# rCSL_ehrpwm_001 register map
Vendor: Texas Instruments
Peripheral module from a debugger description file (folder OMAPL138_C6748).
Registers are 16-bit, access not given, reset 0x0 unless marked. A register's access mark holds for its fields unless they carry their own. Offsets are as the file gives them; lines under a group give offsets from that group; [hi:lo] are bit positions; {n}, {i} and the like mark numbered series; 'fields as' and 'values as' point back to an identical list; <NAME> marks a mode.

## EHRPWM — Enhanced high-resolution pulse width modulator. This is a combination of the ePWM and HRPWM modules.
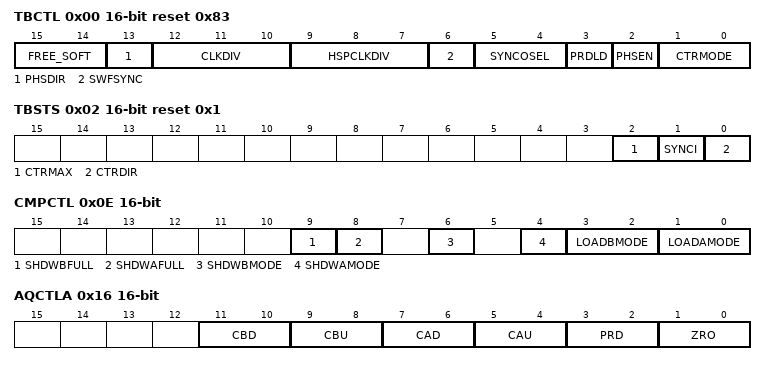
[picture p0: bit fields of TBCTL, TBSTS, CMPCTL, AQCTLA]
0x00 TBCTL rw reset 0x83 — Time-base control
  [15:14] FREE_SOFT — Emulation mode bits.
    0=STOPNEXT; 1=STOPONFULLCYCLE; 2=RUNFREE; 3=RUNFREE
  [13] PHSDIR — Phase direction.
    0=DOWN; 1=UP
  [12:10] CLKDIV — Time-base clock prescale
    0=DIVBY1; 1=DIVBY2; 2=DIVBY4; 3=DIVBY8; 4=DIVBY16; 5=DIVBY32; 6=DIVBY64; 7=DIVBY128
  [9:7] HSPCLKDIV — High speed time-base clock prescale
    0=DIVBY1; 1=DIVBY2; 2=DIVBY4; 3=DIVBY6; 4=DIVBY8; 5=DIVBY10; 6=DIVBY10; 7=DIVBY14
  [6] SWFSYNC — Software forced sync pulse
    0=NOEFFECT; 1=SYNCPULSE
  [5:4] SYNCOSEL — Sync output select
    0=EPWMXSYNCI; 1=TBCTRZERO; 2=TBCTRCMPB; 3=DISABLE
  [3] PRDLD — Active period register load from shadow register select
    0=FROMSHADOW; 1=NOSHADOW
  [2] PHSEN — Counter register load from phase register enable
    0=DISABLE; 1=ENABLE
  [1:0] CTRMODE — Counter mode
    0=UP; 1=DOWN; 2=UPDOWN; 3=STOPFREEZE
0x02 TBSTS reset 0x1 — Time-base status
  [2] CTRMAX rw — Time-base counter max latched status
    0=NOEFFECT; 1=CLEAR
  [1] SYNCI rw — Input sync latched status
    0=NOEFFECT; 1=CLEAR
  [0] CTRDIR ro — Time-base counter direction status
    0=DOWN; 1=UP
0x04 TBPHSHR — Extension for HRPWM phase register. NOTE: although these are documented as part of the HRPWM module, they are actually on the ePWM VBUS, and are therefore represented here.
  [15:8] TBPHSHR rw — High-res extension for TBPHS.
0x06 TBPHS rw — Time-base phase
  [15:0] TBPHS — Time-base counter phase relative to time-base that is supplying sync input.
0x08 TBCTR rw — Time-base counter
0x0A TBPRD rw — Time-base period
  [15:0] TBPRD — Time-base period, i.e. the PWM frequency
0x0E CMPCTL — Counter-compare control
  [9] SHDWBFULL ro — CMPB shadow registers full status flag
    0=NOTFULL; 1=FULL
  [8] SHDWAFULL ro — CMPA shadow registers full status flag
    0=NOTFULL; 1=FULL
  [6] SHDWBMODE rw — CMPB register operating mode
    0=SHADOW; 1=IMMEDIATE
  [4] SHDWAMODE rw — CMPA register operating mode
    0=SHADOW; 1=IMMEDIATE
  [3:2] LOADBMODE rw — CMPB load from shadow select mode
    0=TBCTRZERO; 1=TBCTRPRD; 2=ZEROORPRD; 3=FREEZE
  [1:0] LOADAMODE rw — CMPa load from shadow select mode
    0=TBCTRZERO; 1=TBCTRPRD; 2=ZEROORPRD; 3=FREEZE
0x10 CMPAHR — Extension for HRPWM Counter-compare A. NOTE: although these are documented as part of the HRPWM module, they are actually on the ePWM VBUS, and are therefore represented here.
  [15:8] CMPAHR rw — High-res extension for CMPA.
0x12 CMPA rw — Counter-compare A
  [15:0] CMPA — Compare A value
0x14 CMPB rw — Counter-compare B
  [15:0] CMPB — Compare B value
0x16 AQCTLA — Action-qualifier control for output A
  [all] fields
    0=DONOTHING; 1=EPWMXALOW; 2=EPWMXAHIGH; 3=EPWMXATOGGLE
  [11:10] CBD rw — Action when TBCTR equals active CMPB and counter is decrementing.
  [9:8] CBU rw — Action when TBCTR equals active CMPB and counter is incrementing.
  [7:6] CAD rw — Action when TBCTR equals active CMPA and counter is decrementing.
  [5:4] CAU rw — Action when TBCTR equals active CMPA and counter is incrementing.
  [3:2] PRD rw — Action when TBCTR equals the period.
  [1:0] ZRO rw — Action when TBCTR equals zero.
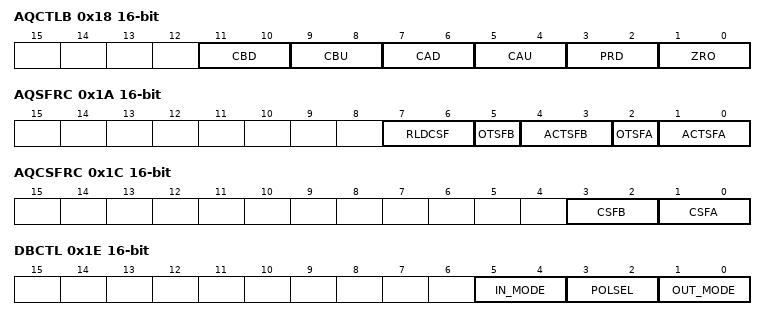
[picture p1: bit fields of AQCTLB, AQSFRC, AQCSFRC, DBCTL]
0x18 AQCTLB — Action-qualifier control for output B
  [all] fields
    0=DONOTHING; 1=EPWMXBLOW; 2=EPWMXBHIGH; 3=EPWMXBTOGGLE
  [11:10] CBD rw — Action when TBCTR equals active CMPB and counter is decrementing.
  [9:8] CBU rw — Action when TBCTR equals active CMPB and counter is incrementing.
  [7:6] CAD rw — Action when TBCTR equals active CMPA and counter is decrementing.
  [5:4] CAU rw — Action when TBCTR equals active CMPA and counter is incrementing.
  [3:2] PRD rw — Action when TBCTR equals the period.
  [1:0] ZRO rw — Action when TBCTR equals zero.
0x1A AQSFRC — Action-qualifier software force
  [7:6] RLDCSF rw — AQCSF active register reload from shadow options
    0=EVTCTRZERO; 1=EVTCTRPRD; 2=ZEROORPRD; 3=IMMEDIATE
  [5] OTSFB rw — One-time s/w forced event on output B
    0=NOEFFECT; 1=EVENT
  [4:3] ACTSFB rw — Action when one-time s/w force B is invoked
    0=DONOTHING; 1=CLEAR; 2=SET; 3=TOGGLE
  [2] OTSFA rw — One-time s/w forced event on output A
    0=NOEFFECT; 1=EVENT
  [1:0] ACTSFA rw — Action when one-time s/w force A is invoked
    0=DONOTHING; 1=CLEAR; 2=SET; 3=TOGGLE
0x1C AQCSFRC — Action-qualifier continuous s/w force
  [3:2] CSFB rw — Continuous software force on output B
    0=DISABLED; 1=LOW; 2=HIGH; 3=DISABLED
  [1:0] CSFA rw — Continuous software force on output A
    0=DISABLED; 1=LOW; 2=HIGH; 3=DISABLED
0x1E DBCTL — Dead-band generator control
  [5:4] IN_MODE rw — Dead band input mode; "FED" is falling edge delay, "RED" is rising edge delay.
    0=AREDAFED; 1=BREDAFED; 2=AREDBFED; 3=BREDBFED
  [3:2] POLSEL rw — Polarity select
    0=ACTIVEHIGH; 1=ALC; 2=AHC; 3=ACTIVELOW
  [1:0] OUT_MODE rw — Dead-band output mode control; "FED" is falling edge delay, "RED" is rising edge delay.
    0=BYPASS; 1=NOREDBFED; 2=AREDNOFED; 3=AREDBFED
0x20 DBRED — Dead-band generator rising edge delay count
  [9:0] DEL rw — Rising edge delay count. 10-bit counter.
0x22 DBFED — Dead-band generator rising edge delay count
  [9:0] DEL rw — Falling edge delay count. 10-bit counter.
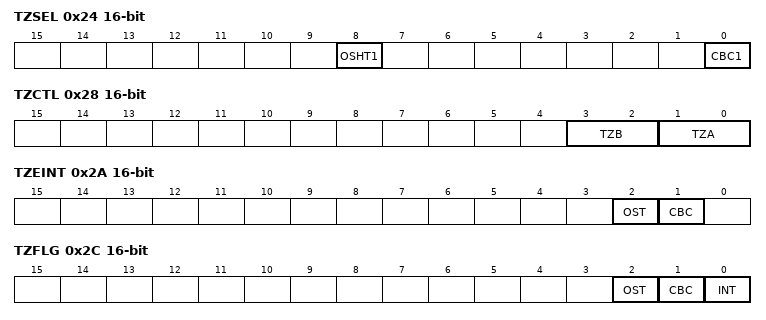
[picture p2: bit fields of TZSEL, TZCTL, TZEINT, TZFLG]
0x24 TZSEL — Trip-zone select
  [8] OSHT1 rw — Trip zone 1 as one-shot source select
    0=DISABLE; 1=ENABLE
  [0] CBC1 rw — Trip zone 1 as cycle-by-cycle source select
    0=DISABLE; 1=ENABLE
0x28 TZCTL — Trip-zone control
  [3:2] TZB rw — When TZ event occurs, take this action on EPWMxB.
    0=TRISTATE; 1=FORCEHIGH; 2=FORCELOW; 3=DONOTHING
  [1:0] TZA rw — When TZ event occurs, take this action on EPWMxA.
    0=TRISTATE; 1=FORCEHIGH; 2=FORCELOW; 3=DONOTHING
0x2A TZEINT — Trip-zone interrupt enable
  [2] OST rw — Trip-zone one-shot interrupt enable
    0=DISABLE; 1=ENABLE
  [1] CBC rw — Trip-zone cycle-by-cycle interrupt enable
    0=DISABLE; 1=ENABLE
0x2C TZFLG — Trip-zone flag
  [2] OST ro — Trip-zone one-shot event latched status flag
    0=NOEVENT; 1=EVENT
  [1] CBC ro — Trip-zone cycle-by-cycle event latched status flag
    0=NOEVENT; 1=EVENT
  [0] INT ro — Trip-zone interrupt latched status flag
    0=NOINT; 1=INT
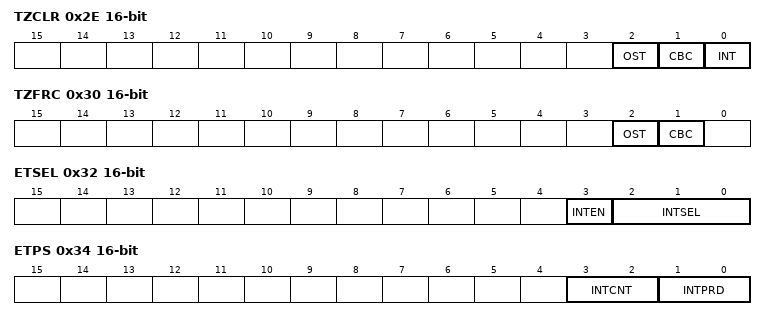
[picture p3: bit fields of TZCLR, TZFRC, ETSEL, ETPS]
0x2E TZCLR — Trip-zone clear
  [all] fields
    0=NOEFFECT; 1=CLEAR
  [2] OST rw — Clear flag for OST latch
  [1] CBC rw — Clear flag for CBC trip latch
  [0] INT rw — Clear global interrupt flag
0x30 TZFRC — Trip-zone force
  [2] OST rw — Force OST event
    0=NOEFFECT; 1=FORCE
  [1] CBC rw — Force CBC event
    0=NOEFFECT; 1=FORCE
0x32 ETSEL — Event-trigger selection
  [3] INTEN rw — Enable ePWM interrupt (EPWMX_INT) generation.
    0=DISABLE; 1=ENABLE
  [2:0] INTSEL rw — EPWMx_INT selection options
    1=TBCTREQUZERO; 2=TBCTREQUPRD; 4=TBCTREQUCMPAINC; 5=TBCTREQUCMPADEC; 6=TBCTREQUCMPBINC; 7=TBCTREQUCMPBDEC
0x34 ETPS — Event-trigger prescale
  [3:2] INTCNT ro — EPWMx_INT counter
    0=NOEVENTS; 1=ONEEVENT; 2=TWOEVENTS; 3=THREEEVENTS
  [1:0] INTPRD rw — EPWMx_INT period select
    0=DISABLE; 1=FIRSTEVENT; 2=SECONDEVENT; 3=THIRDEVENT
0x36 ETFLG — Event-trigger flag
  [0] INT ro — Latched EPWMx_INT status flag
    0=NOINT; 1=INT
0x38 ETCLR — Event-trigger clear
  [0] INT rw — Latched EPWMx_INT flag clear
    0=NOEFFECT; 1=CLEAR
0x3A ETFRC — Event-trigger force
  [0] INT ro — INT force
    0=NOEFFECT; 1=FORCE
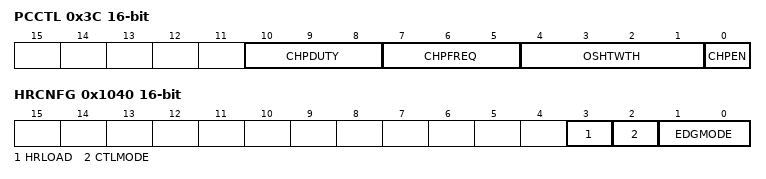
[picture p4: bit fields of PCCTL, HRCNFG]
0x3C PCCTL — PWM-chopper control
  [10:8] CHPDUTY rw — Chopping clock duty cycle
    {v}={v+1}DIV8 (v=0..6)
  [7:5] CHPFREQ rw — Chopping clock frequency
    {v}=DIVBY{v+1} (v=0..7)
  [4:1] OSHTWTH rw — One-shot pulse width
  [0] CHPEN rw — PWM-chopping enable
    0=DISABLE; 1=ENABLE
0x5C REVID 32-bit ro reset 0x44D10903 — Revision ID
  [31:0] REV
0x1040 HRCNFG — HRPWM configuration. Note: this register actually lies within the HRPWM memory space, which is offset by 0x1000 from ePWM's base address. So this large offset accounts for that.
  [3] HRLOAD rw — Shadow mode bit: selects time event that loads CMPAHR value into the active register.
    0=CTREQUZERO; 1=CTREQUPRD
  [2] CTLMODE rw — Control mode bits; selects register that controls the MEP.
    0=CMPAHR; 1=TBPHSHR
  [1:0] EDGMODE rw — Edge mode bits: selects the edge of the PWM that is controlled by the MEP.
    0=DISABLED; 1=RISINGEDGE; 2=FALLINGEDGE; 3=BOTHEDGES
